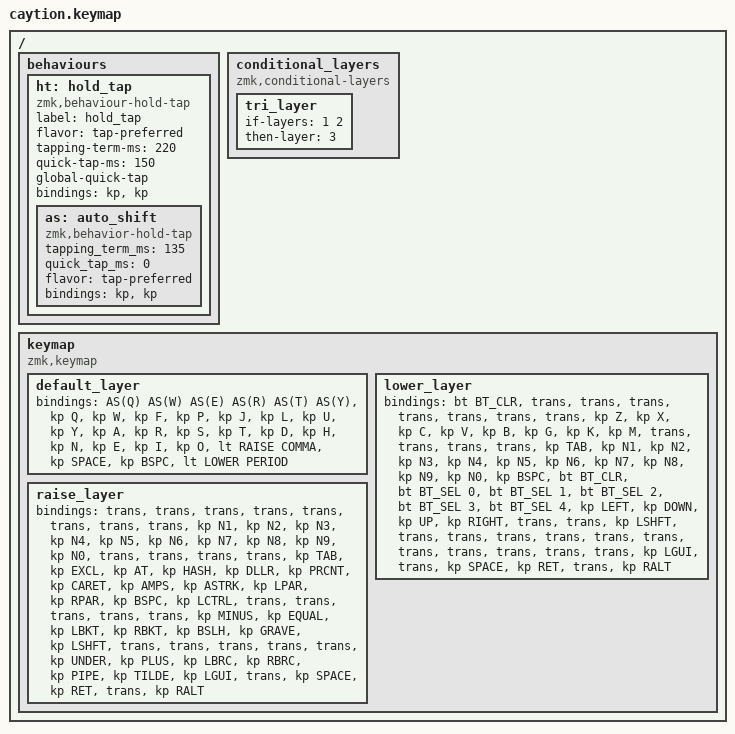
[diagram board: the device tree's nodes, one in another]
/*
 * Copyright (c) 2020 The ZMK Contributors
 *
 * SPDX-License-Identifier: MIT
 */

#include <behaviors.dtsi>
#include <dt-bindings/zmk/keys.h>
#include <dt-bindings/zmk/bt.h>

#define HRML(k1,k2,k3,k4) &ht LSHFT k1  &ht LALT k2  &ht LCTRL k3  &ht LGUI k4
#define HRML(k1,k2,k3,k4) &ht RGUI k1  &ht RCTRL k2  &ht RALT k3  &ht RSHFT k4
#define AS(keycode) &as LS(keycode) keycode     // Autoshift Macro

/ {
        behaviours {
                ht: hold_tap{
                label = "hold_tap";
                compatible = "zmk,behaviour-hold-tap";
                #binding-cells = <2>;
                flavor = "tap-preferred";
                tapping-term-ms = <220>;
                quick-tap-ms = <150>;
                global-quick-tap;
                bindings = <&kp>, <&kp>;
                as: auto_shift {
                compatible = "zmk,behavior-hold-tap";
                #binding-cells = <2>;
                tapping_term_ms = <135>;
                quick_tap_ms = <0>;
                flavor = "tap-preferred";
                bindings = <&kp>, <&kp>;
                };
                };
        };

        conditional_layers {
                compatible = "zmk,conditional-layers";
                tri_layer {
                        if-layers = <1 2>;
                        then-layer = <3>;
                };
        };

        keymap {
                compatible = "zmk,keymap";
                default_layer {
                        bindings = <
                        AS(Q) AS(W) AS(E) AS(R) AS(T) AS(Y) // Autoshift applied for QWERTY keys
// -----------------------------------------------------------------------------------------
// |   Q   |   W   |   F   |   P   |                        |   J   |   L   |   U   |   Y   |     
     &kp Q   &kp W   &kp F   &kp P                            &kp J   &kp L   &kp U   &kp Y
// |   A   |   R   |   S   |   T   |   D   |        |   H   |   N   |   E   |   I   |   O   |      
     &kp A   &kp R   &kp S   &kp T   &kp D            &kp H   &kp N   &kp E   &kp I   &kp O
//                 | &lt RAISE COMMA | &kp SPACE |        |  &kp BSPC | &lt LOWER PERIOD|
                     &lt RAISE COMMA   &kp SPACE             &kp BSPC   &lt LOWER PERIOD
                        >;
                };
                lower_layer {
                        bindings = <
// -----------------------------------------------------------------------------------------
// |       |       |   -   |   +   |                            |   :   |   ;   |   "   |   '   |     
&bt BT_CLR  &trans  &trans  &trans                               &trans  &trans  &trans  &trans
// |   Z   |   X   |   C   |   V   |   B   |            |   G   |   K   |   M   |   !   |   ?   |      
     &kp Z   &kp X   &kp C   &kp V   &kp B                &kp G   &kp K   &kp M
//                          | trans | SPC |             | RSE   | trans |
                             &trans  &trans              &trans  &trans
                        
   &kp TAB    &kp N1       &kp N2       &kp N3       &kp N4       &kp N5         &kp N6   &kp N7   &kp N8 &kp N9    &kp N0 &kp BSPC
   &bt BT_CLR &bt BT_SEL 0 &bt BT_SEL 1 &bt BT_SEL 2 &bt BT_SEL 3 &bt BT_SEL 4   &kp LEFT &kp DOWN &kp UP &kp RIGHT &trans &trans
   &kp LSHFT  &trans       &trans       &trans       &trans       &trans         &trans   &trans   &trans &trans    &trans &trans
                                    &kp LGUI     &trans       &kp SPACE      &kp RET  &trans   &kp RALT
                        >;
                };

                raise_layer {
                        bindings = <
// -----------------------------------------------------------------------------------------
// |   /   |   @   |   #   |   $   |                          |   %   |   ^   |  &   |   *  |     
    &trans  &trans  &trans  &trans                             &trans  &trans  &trans  &trans
// |   1   |   2   |   3   |   4   |   5   |          |   6   |   7   |   8   |   9  |   0  |  
    &kp N1  &kp N2  &kp N3   &kp N4  &kp N5             &kp N6  &kp N7 &kp N8  &kp N9  &kp N0
//                          | LWR | SPC |                                   |      | ALT |
                             &trans   &trans                                 &trans  &trans
   &kp  TAB  &kp EXCL &kp AT &kp HASH &kp DLLR &kp PRCNT   &kp CARET &kp AMPS  &kp ASTRK &kp LPAR &kp RPAR &kp BSPC
   &kp LCTRL &trans   &trans &trans   &trans   &trans      &kp MINUS &kp EQUAL &kp LBKT  &kp RBKT &kp BSLH &kp GRAVE
   &kp LSHFT &trans   &trans &trans   &trans   &trans      &kp UNDER &kp PLUS  &kp LBRC  &kp RBRC &kp PIPE &kp TILDE
                             &kp LGUI &trans   &kp SPACE   &kp RET   &trans    &kp RALT
                        >;
                };
        };
};
